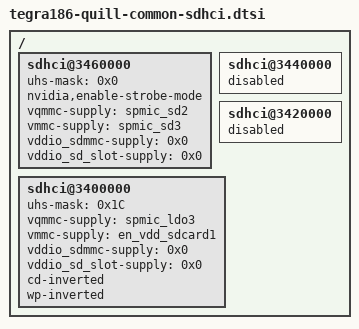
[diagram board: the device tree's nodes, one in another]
/ {
	sdhci@3460000 {
		uhs-mask = <0x0>; /*enable HS400 mode*/
		nvidia,enable-strobe-mode;
		vqmmc-supply = <&spmic_sd2>;
		vmmc-supply = <&spmic_sd3>;
		vddio_sdmmc-supply = <0x0>;
		vddio_sd_slot-supply = <0x0>;
		status = "okay";
	};

	sdhci@3440000 {
		status = "disabled";
	};

	sdhci@3420000 {
		status = "disabled";
	};

	sdhci@3400000 {
		uhs-mask = <0x1C>;
		vqmmc-supply = <&spmic_ldo3>;
		vmmc-supply = <&en_vdd_sdcard1>;
		vddio_sdmmc-supply = <0x0>;
		vddio_sd_slot-supply = <0x0>;
		cd-inverted;
		wp-inverted;
		status = "okay";
	};
};
